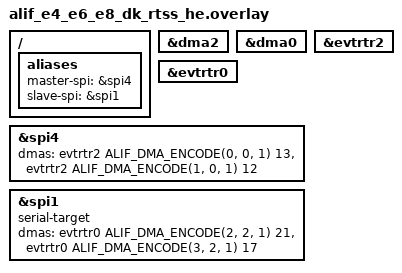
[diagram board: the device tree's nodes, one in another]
/* Copyright (C) 2025 Alif Semiconductor - All Rights Reserved.
 * Use, distribution and modification of this code is permitted under the
 * terms stated in the Alif Semiconductor Software License Agreement
 *
 * You should have received a copy of the Alif Semiconductor Software
 * License Agreement with this file. If not, please write to:
 * contact@alifsemi.com, or visit: https://alifsemi.com/license
 *
 */

/* For SPI master SS(slave select) as:
 * - H/W controlled (default):
 *   - use SS pinmux as H/W
 *     - example for SPI1 as master "PIN_P14_7__SPI1_SS0_C"
 *  "OR"
 * - S/W controlled using gpio:
 *   - use SS pinmux as gpio
 *     - example for SPI1 as master "PIN_P14_7__GPIO"
 *   - define cs-gpios property
 *     - example for SPI1 as master
 *        cs-gpios = <&gpio14 7 GPIO_ACTIVE_LOW>;
 */

/* default SPI master SS(slave select) is H/W controlled,
 * enable this to use as S/W controlled using gpio.
 */
#define SPI_MASTER_SS_SW_CONTROLLED_GPIO   0

/* Enable to use Event Router driver instead of manual configuration
 * When enabled:
 * - DMA routing goes through event router driver
 * - Manual event router configuration in main.c is disabled
 * When disabled:
 * - Direct DMA approach with manual event router programming
 */
#define USE_EVENT_ROUTER_DRIVER   1

/* setting SPI4(LPSPI) as master and SPI1 instance as slave. */
/ {
	aliases {
		master-spi = &spi4;
		slave-spi = &spi1;
	};
};

&dma2 {
	status = "okay";
};

&dma0 {
	status = "okay";
};

#if USE_EVENT_ROUTER_DRIVER
/* Event Router driver approach: route through event router */
#include <zephyr/dt-bindings/dma/alif_dma_event_router.h>

&evtrtr2 {
	status = "okay";
};

&evtrtr0 {
	status = "okay";
};

&spi4 { /* LPSPI */
	status = "okay";
	/*
	 * Cell 0: ALIF_DMA_ENCODE(channel, dma_group, handshake)
	 *   - channel: Physical DMA channel (0 for TX, 1 for RX)
	 *   - dma_group: Input source selection (0) - selects which peripheral input
	 *   - handshake: Enable hardware handshaking (1 for SPI)
	 * Cell 1: Peripheral request number (13 for TX, 12 for RX)
	 */
	dmas = <&evtrtr2 ALIF_DMA_ENCODE(0, 0, 1) 13>,
	       <&evtrtr2 ALIF_DMA_ENCODE(1, 0, 1) 12>;
/* If user wants to use dma0 for master spi(spi4) with event router:
 * dmas = <&evtrtr0 ALIF_DMA_ENCODE(0, 2, 1) 25>,
 *        <&evtrtr0 ALIF_DMA_ENCODE(1, 2, 1) 24>;
 */
	dma-names = "txdma", "rxdma";

#if SPI_MASTER_SS_SW_CONTROLLED_GPIO
	cs-gpios = <&gpio11 7 GPIO_ACTIVE_LOW>;
	/* as we are testing Loopback on the same board,
	 * make sure master interrupt priority is
	 * higher than slave interrupt priority.
	 */
	interrupts = <46 0>;
#endif /* SPI_MASTER_SS_SW_CONTROLLED_GPIO */
};

&spi1 { /* SPI1 */
	status = "okay";
	serial-target;
	/*
	 * Cell 0: ALIF_DMA_ENCODE(channel, dma_group, handshake)
	 *   - channel: Physical DMA channel (2 for TX, 3 for RX)
	 *   - dma_group: Input source selection (2) - selects which peripheral input
	 *   - handshake: Enable hardware handshaking (1 for SPI)
	 * Cell 1: Peripheral request number (21 for TX, 17 for RX)
	 */
	dmas = <&evtrtr0 ALIF_DMA_ENCODE(2, 2, 1) 21>,
	       <&evtrtr0 ALIF_DMA_ENCODE(3, 2, 1) 17>;
	dma-names = "txdma", "rxdma";

#if SPI_MASTER_SS_SW_CONTROLLED_GPIO
	interrupts = <138 1>;
#endif
};

#else
/* Direct DMA approach: manual event router configuration in main.c */

&spi4 { /* LPSPI */
	status = "okay";
	/* Direct PL330 DMA specifier format:
	 * Cell 0: PL330 physical channel (0 for TX, 1 for RX)
	 * Cell 1: PL330 peripheral request (13 for TX, 12 for RX)
	 * Note: Event router is manually configured in main.c
	 */
	dmas = <&dma2 0 13>, <&dma2 1 12>;
/* If user want to use dma0 for master spi(spi4),
 * add below dmas property:
 * dmas = <&dma0 0 25>, <&dma0 1 24>;
 */
	dma-names = "txdma", "rxdma";

#if SPI_MASTER_SS_SW_CONTROLLED_GPIO
	cs-gpios = <&gpio11 7 GPIO_ACTIVE_LOW>;
	/* as we are testing Loopback on the same board,
	 * make sure master interrupt priority is
	 * higher than slave interrupt priority.
	 */
	interrupts = <46 0>;
#endif /* SPI_MASTER_SS_SW_CONTROLLED_GPIO */
};

&spi1 { /* SPI1 */
	status = "okay";
	serial-target;
	/* Direct PL330 DMA specifier format:
	 * Cell 0: PL330 physical channel (2 for TX, 3 for RX)
	 * Cell 1: PL330 peripheral request (21 for TX, 17 for RX)
	 * Note: Event router is manually configured in main.c
	 */
	dmas = <&dma0 2 21>, <&dma0 3 17>;
	dma-names = "txdma", "rxdma";

#if SPI_MASTER_SS_SW_CONTROLLED_GPIO
	interrupts = <138 1>;
#endif
};

#endif /* USE_EVENT_ROUTER_DRIVER */

#if SPI_MASTER_SS_SW_CONTROLLED_GPIO
/* use SPI master SS pinmux as gpio. */
&pinctrl_lpspi{
	group0 {
		pinmux = < PIN_P11_4__LPSPI_MISO_B >,
			 < PIN_P11_5__LPSPI_MOSI_B >,
			 < PIN_P11_6__LPSPI_SCLK_B >,
			 < PIN_P11_7__GPIO >;
		read-enable = < 0x1 >;
	};
};

&gpio11 {
	status = "okay";
};
#endif /* SPI_MASTER_SS_SW_CONTROLLED_GPIO */
